# CY8C5888LTI_LP097 register map
File version: 0.1
Registers are 8-bit, read-write, no defined reset value unless marked. A register's access mark holds for its fields unless they carry their own. Offsets are from the block's base; [hi:lo] are bit positions; {n}, {i} and the like mark numbered series; 'fields as' and 'values as' point back to an identical list.

## Comp_1
Base 0x00000000
0x400043A7 Comp_1_Comp_PM_ACT_CFG — Active Power Mode Configuration Register 7
  [3:0] en_cmp — Enable comparator. Populated subsystems are counted from the LSB, for example bit 0 corresponds to comparator 0
0x400043B7 Comp_1_Comp_PM_STBY_CFG — Standby Power Mode Configuration Register 7
  fields as Comp_1_Comp_PM_ACT_CFG
0x40004634 Comp_1_Comp_TR0 — Comparator Trim Register_TR0
  [4:0] trimA_4_0_ — Sets the trim value to be added to the P-type load for offset calibration
    0=TRIMA_0 (Does not add any offset); {v}=TRIMA_POS_SIDE_{v} (Adds offset of ~{v}mV to the positive side) (v=1..8); {v}=TRIMA_NEG_SIDE_{v-9} (Adds offset of ~{v-10}mV to the negative side) (v=10..18)
0x40004635 Comp_1_Comp_TR1 — Comparator Trim Register_TR1
  [4:0] trimB_4_0_ — Sets the trim value to be added to the N-type load for offset calibration
    0=TRIMB_0 (Does not add any offset); {v}=TRIMB_NEG_SIDE_{v} (Adds offset of ~{v}mV to the negative side) (v=1..8); 10=TRIMB_9 (Does not add any offset); {v}=TRIMB_POS_SIDE_{v-10} (Adds offset of ~{v-10}mV to the positive side) (v=11..18)
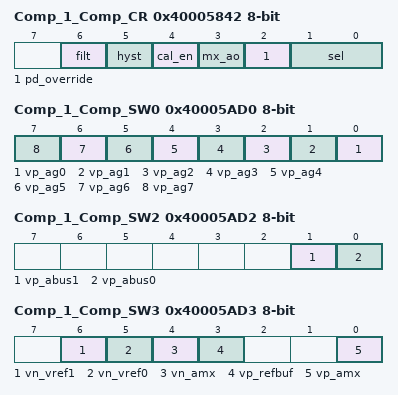
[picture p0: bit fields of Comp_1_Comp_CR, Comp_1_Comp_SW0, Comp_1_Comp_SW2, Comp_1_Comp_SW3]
0x40005842 Comp_1_Comp_CR — Comparator Control Register
  [6] filt — enables a glitch filter at the output of the comparator
    0=FILT_DISABLE (Disable glitch filter); 1=FILT_ENABLE (Enable glitch filter)
  [5] hyst — enables a hysteresis of 10mV typ
    1=HYST_DISABLE (Disable hysteresis); 0=HYST_ENABLE (Enable hysteresis)
  [4] cal_en — enables shorting of the two comparator inputs for trim calibration purposes
    0=CAL_EN_DISABLE (Disable calibration); 1=CAL_EN_ENABLE (Enable calibration)
  [3] mx_ao — comparator sleep always-on logic mux control
    0=MX_AO_BYPASS (Bypass comparator sleep always-on logic); 1=MX_AO_ENABLE (Enable comparator sleep always-on logic)
  [2] pd_override — Power down override to allow comparator to continue operating during sleep
    0=PD_OVERRIDE_DISABLE (Don't override power down); 1=PD_OVERRIDE_ENABLE (Override power down)
  [1:0] sel — Selects the mode of operation of the comparator
    0=SEL_SLOW (slow mode); 1=SEL_FAST (fast mode); 2=SEL_LP (ultra low power mode); 3=SEL_ILLEGAL (Illegal Mode)
0x40005AD0 Comp_1_Comp_SW0 — Comparator Analog Routing Register 0
  [all] fields
    0=AG_NC (not connected); 1=AG_CONNECTED (Connect to Analog Global)
  [n] vp_ag{n} (n=0..7) — Connect positive voltage input to analog global of same side
0x40005AD2 Comp_1_Comp_SW2 — Comparator Analog Routing Register 2
  [1] vp_abus1 — Connect positive voltage input to analog (local) bus of the same side
    0=ABUS_NC (not connected); 1=ABUS_CONNECTED (Connect to Analog (local) Bus)
  [0] vp_abus0 — Connect positive voltage input to analog (local) bus of the same side
    values as vp_abus1
0x40005AD3 Comp_1_Comp_SW3 — Comparator Analog Routing Register 3
  [6] vn_vref1 — Connect negative voltage input to Voltage Reference 1
    0=VREF_NC (not connected); 1=VREF_CONNECTED (Connect to Voltage Reference)
  [5] vn_vref0 — Connect negative voltage input to Voltage Reference 0
    values as vn_vref1
  [4] vn_amx — Connect negative voltage input to Analog Mux Bus
    0=AMX_NC (not connected); 1=AMX_CONNECTED (Connect to AMUXBUS)
  [3] vp_refbuf — Connect positive voltage input to CapSense reference buffer channel
    0=VP_REFBUF_ENABLED (disable); 1=VP_REFBUF_DISABLED (enable)
  [0] vp_amx — Connect positive voltage input to Analog Mux Bus
    values as vn_amx
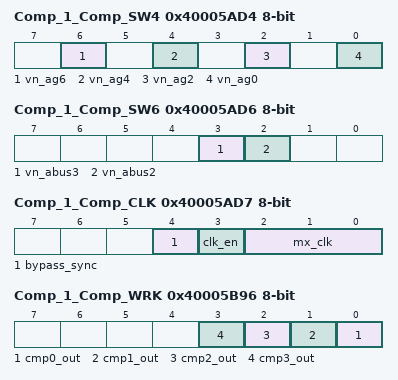
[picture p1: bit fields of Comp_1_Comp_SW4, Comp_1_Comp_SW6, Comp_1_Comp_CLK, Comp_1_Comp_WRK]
0x40005AD4 Comp_1_Comp_SW4 — Comparator Analog Routing Register 4
  [all] fields
    values as the fields of Comp_1_Comp_SW0
  [6] vn_ag6 — Connect negative voltage input to analog global of same side
  [4] vn_ag4 — Connect negative voltage input to analog global of same side
  [2] vn_ag2 — Connect negative voltage input to analog global of same side
  [0] vn_ag0 — Connect negative voltage input to analog global of same side
0x40005AD6 Comp_1_Comp_SW6 — Comparator Analog Routing Register 6
  [3] vn_abus3 — Connect negative voltage input to analog (local) bus of the same side
    values as Comp_1_Comp_SW2.vp_abus1
  [2] vn_abus2 — Connect negative voltage input to analog (local) bus of the same side
    values as Comp_1_Comp_SW2.vp_abus1
0x40005AD7 Comp_1_Comp_CLK — Comparator Clock Control Register
  [4] bypass_sync — Bypass Synchronization
    0=Synchronization not bypassed (Synchronization enabled); 1=Synchronization bypassed (Synchronization disabled)
  [3] clk_en — Clock gating control
    0=disable clock; 1=enable clock
  [2:0] mx_clk — Clock Selection
    {v}=Select clk_a{v} and clk_a{v}_dig (v=0..3); 4=Select UDB generated clock
0x40005B96 Comp_1_Comp_WRK — Comparator output working register
  [n] cmp{n}_out ro (n=0..3) — Comparator Output

## Ultrasonic_Pulse_Counter — Count7 debug registers
Base 0x00000000
0x40006575 COUNT 7-bit — Count value register
0x40006585 PERIOD 7-bit — Count7 period register

## Vssa_Buffer
Base 0x00000000
0x400043A4 PM_ACT_CFG4 — Active Power Mode Configuration Register 4
  [3:0] EN_OPAMP — Enables subsystems during active power mode
    0=Blk_0 (Enables analog linear output buffer for Opamp block 0); 2=Blk_1 (Enables analog linear output buffer for Opamp block 1); 4=Blk_2 (Enables analog linear output buffer for Opamp block 2); 8=Blk_3 (Enables analog linear output buffer for Opamp block 3)
0x400043B4 PM_STBY_CFG4 — Standby Power Mode Configuration Register 4
  [3:0] EN_OPAMP — Enables subsystems during standby power mode
    values as PM_ACT_CFG4.EN_OPAMP
0x40004626 OPAMP__TR0 — Analog Output Buffer Trim Register 0
  [4:0] offset_trim — Offset Trim: 420uV typical step size; +/- 6.8mV offset trimmable range
0x40004627 OPAMP__TR1 — Analog Output Buffer Trim Register 1
0x4000585E OPAMP__CR — Analog Output Buffer Configuration Register
  [1:0] pwr_mode — Power Mode
    0=Default_Fast (Default Power mode Fast); 1=Slow (Power Mode Slow); 2=Medium (Power Mode Medium); 3=Fast (Power Mode Fast)
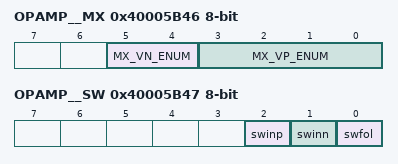
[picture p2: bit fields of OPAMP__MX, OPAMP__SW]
0x40005B46 OPAMP__MX — Analog Buffer Input Selection Register
  [5:4] MX_VN_ENUM — MUX select VN (Negative terminal input)
    0=OPAMP0_MX_VN_DEFAULT (Default - Not Connected (NC)); 1=OPAMP0_MX_VN_AG4 (MUX Selection AGL(4)); 2=OPAMP0_MX_VN_AG6 (MUX Selection AGL(6)); 3=OPAMP0_MX_VN_0x3 (Reserved (NC))
  [3:0] MX_VP_ENUM — MUX select VP (Positive terminal input)
    0=OPAMP0_MX_VP_DEFAULT (Default - Not Connected (NC)); {v}=OPAMP0_MX_VP_AG{v+3} (MUX Selection AGL({v+3})) (v=1..4); {v}=OPAMP0_MX_VP_ABUS{v-5} (MUX Selection ABUSL({v-5})) (v=5..8); 9=OPAMP0_MX_VP_VREF (MUX Selection: OPAMP Voltage Reference); {v}=OPAMP0_MX_VP_H_{0x0+v} (Reserved (NC)) (v=10..15)
0x40005B47 OPAMP__SW — Analog Buffer Routing Switch Register
  [2] swinp — Switch Enable Positive Input
  [1] swinn — Switch Enable Negative Input
  [0] swfol — Switch Enable Follow

## Ultrasonic_Set_Reg
Base 0x00000000
0x40006574 Ultrasonic_Set_Reg_CONTROL_REG
